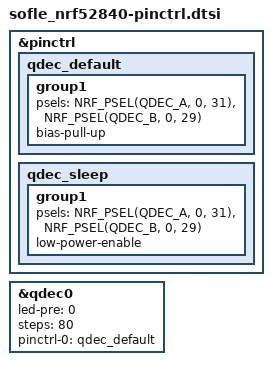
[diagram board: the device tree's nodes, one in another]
&pinctrl {
    qdec_default: qdec_default {
        group1 {
            psels = <NRF_PSEL(QDEC_A, 0, 31)>,
                    <NRF_PSEL(QDEC_B, 0, 29)>;
            bias-pull-up;
        };
    };
    qdec_sleep: qdec_sleep {
        group1 {
            psels = <NRF_PSEL(QDEC_A, 0, 31)>,
                    <NRF_PSEL(QDEC_B, 0, 29)>;
            low-power-enable;
        };
    };
};

// Set up the QDEC hardware based driver and give it the same label as the deleted node.
encoder: &qdec0 {
    status = "okay";
    led-pre = <0>;
    steps = <80>;
    pinctrl-0 = <&qdec_default>;
    pinctrl-names = "default";
};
